VERSION ""

NS_ :

BS_:

BU_: PCU
VAL_TABLE_ a 15 "Fault" 14 "TBD" 13 "TBD" 12 "TBD" 11 "TBD" 10 "TBD" 9 "TBD" 8 "Power Up" 7 "Batt Temp High - Cooling" 6 "Batt Temp Low - Heating" 5 "Charge Complete" 4 "OCV Measure In Prg" 3 "Charging" 2 "Ready To Charge" 1 "Discharge" 0 "Park" ;

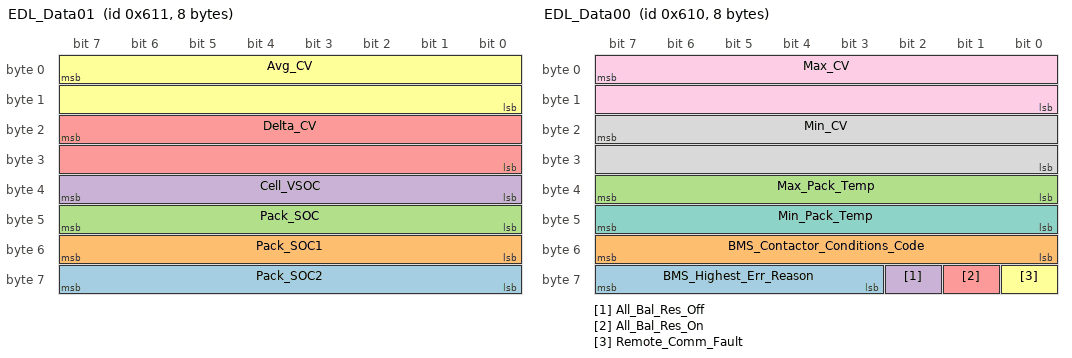
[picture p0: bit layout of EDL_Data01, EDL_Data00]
BO_ 1553 EDL_Data01: 8 Vector__XXX
 SG_ Pack_SOC2 : 63|8@0+ (0.4,0) [0|0] "%" Vector__XXX
 SG_ Pack_SOC1 : 55|8@0+ (0.4,0) [0|0] "%" Vector__XXX
 SG_ Pack_SOC : 47|8@0+ (0.4,0) [0|0] "%" Vector__XXX
 SG_ Cell_VSOC : 39|8@0+ (0.4,0) [0|0] "%" Vector__XXX
 SG_ Delta_CV : 23|16@0+ (0.00244140625,0) [0|0] "Volts" Vector__XXX
 SG_ Avg_CV : 7|16@0+ (0.00244140625,0) [0|0] "Volts" Vector__XXX

BO_ 1827 History_Flt_Msg: 8 Vector__XXX
 SG_ History_Flt_Hi_Cont_Coil_Current : 45|1@0+ (1,0) [0|0] "" Vector__XXX
 SG_ History_Flt_12V_Input_UV_Warning : 44|1@0+ (1,0) [0|0] "" Vector__XXX
 SG_ History_Flt_String_V_Mismatch : 43|1@0+ (1,0) [0|0] "" Vector__XXX
 SG_ History_Flt_Slave_Comm : 42|1@0+ (1,0) [0|0] "" Vector__XXX
 SG_ History_Flt_Hi_DChg_During_Chg : 41|1@0+ (1,0) [0|0] "" Vector__XXX
 SG_ History_Flt_Lo_DChg_During_Chg : 40|1@0+ (1,0) [0|0] "" Vector__XXX
 SG_ History_Flt_12V_Input_Under_Volt : 39|1@0+ (1,0) [0|0] "" Vector__XXX
 SG_ History_Flt_Sec_ContB_Open : 36|1@0+ (1,0) [0|0] "" Vector__XXX
 SG_ History_Flt_Over_Cur_Regulation : 38|1@0+ (1,0) [0|0] "" Vector__XXX
 SG_ History_Flt_No_PCU_Data : 37|1@0+ (1,0) [0|0] "" Vector__XXX
 SG_ History_Flt_Cont2_Stuck_Open : 35|1@0+ (1,0) [0|0] "" Vector__XXX
 SG_ History_Flt_Cont2_Dropout_2nd : 32|1@0+ (1,0) [0|0] "" Vector__XXX
 SG_ History_Flt_Cont2_Dropout_1st : 33|1@0+ (1,0) [0|0] "" Vector__XXX
 SG_ History_Flt_Cont1_Stuck_Open : 34|1@0+ (1,0) [0|0] "" Vector__XXX
 SG_ History_Flt_Under_Volt_B : 26|1@0+ (1,0) [0|0] "" Vector__XXX
 SG_ History_Flt_Under_Volt_A : 27|1@0+ (1,0) [0|0] "" Vector__XXX
 SG_ History_Flt_Under_Temp : 20|1@0+ (1,0) [0|0] "" Vector__XXX
 SG_ History_Flt_SPI : 31|1@0+ (1,0) [0|0] "" Vector__XXX
 SG_ History_Flt_Sec_Stuck_On : 7|1@0+ (1,0) [0|0] "" Vector__XXX
 SG_ History_Flt_Sec_ContA_Open : 10|1@0+ (1,0) [0|0] "" Vector__XXX
 SG_ History_Flt_PChg_Short : 11|1@0+ (1,0) [0|0] "" Vector__XXX
 SG_ History_Flt_PChg_Retry : 14|1@0+ (1,0) [0|0] "" Vector__XXX
 SG_ History_Flt_PChg : 15|1@0+ (1,0) [0|0] "" Vector__XXX
 SG_ History_Flt_Pack_Volt_AD : 1|1@0+ (1,0) [0|0] "" Vector__XXX
 SG_ History_Flt_Over_Volt_B : 28|1@0+ (1,0) [0|0] "" Vector__XXX
 SG_ History_Flt_Over_Volt_A : 29|1@0+ (1,0) [0|0] "" Vector__XXX
 SG_ History_Flt_Over_Temp : 21|1@0+ (1,0) [0|0] "" Vector__XXX
 SG_ History_Flt_Over_Cur : 30|1@0+ (1,0) [0|0] "" Vector__XXX
 SG_ History_Flt_No_Chg_Cur : 18|1@0+ (1,0) [0|0] "" Vector__XXX
 SG_ History_Flt_Int_Iso : 8|1@0+ (1,0) [0|0] "" Vector__XXX
 SG_ History_Flt_Fan_Cur_Lo : 22|1@0+ (1,0) [0|0] "" Vector__XXX
 SG_ History_Flt_Fan_Cur_Hi : 23|1@0+ (1,0) [0|0] "" Vector__XXX
 SG_ History_Flt_Ext_Iso : 9|1@0+ (1,0) [0|0] "" Vector__XXX
 SG_ History_Flt_Cur_B_Lo_AD : 3|1@0+ (1,0) [0|0] "" Vector__XXX
 SG_ History_Flt_Cur_B_Hi_AD : 2|1@0+ (1,0) [0|0] "" Vector__XXX
 SG_ History_Flt_Cur_A_Lo_AD : 5|1@0+ (1,0) [0|0] "" Vector__XXX
 SG_ History_Flt_Cur_A_Hi_AD : 4|1@0+ (1,0) [0|0] "" Vector__XXX
 SG_ History_Flt_Cont1_Dropout_2nd : 12|1@0+ (1,0) [0|0] "" Vector__XXX
 SG_ History_Flt_Cont1_Dropout_1st : 13|1@0+ (1,0) [0|0] "" Vector__XXX
 SG_ History_Flt_Cont2_Stuck_On : 17|1@0+ (1,0) [0|0] "" Vector__XXX
 SG_ History_Flt_Cont2_Retry : 16|1@0+ (1,0) [0|0] "" Vector__XXX
 SG_ History_Flt_Cont1_Stuck_On : 25|1@0+ (1,0) [0|0] "" Vector__XXX
 SG_ History_Flt_Cont1_Retry : 24|1@0+ (1,0) [0|0] "" Vector__XXX
 SG_ History_Flt_Bus_Volt_AD : 0|1@0+ (1,0) [0|0] "" Vector__XXX
 SG_ History_Flt_Bd_Under_Temp : 6|1@0+ (1,0) [0|0] "" Vector__XXX
 SG_ History_Flt_Bd_Over_Temp : 19|1@0+ (1,0) [0|0] "" Vector__XXX

BO_ 1826 Latched_Flt_Msg: 8 Vector__XXX
 SG_ Latched_Flt_Hi_Cont_Coil_Current : 45|1@0+ (1,0) [0|0] "" Vector__XXX
 SG_ Latched_Flt_12V_Input_UV_Warning : 44|1@0+ (1,0) [0|0] "" Vector__XXX
 SG_ Latched_Flt_String_V_Mismatch : 43|1@0+ (1,0) [0|0] "" Vector__XXX
 SG_ Latched_Flt_Slave_Comm : 42|1@0+ (1,0) [0|0] "" Vector__XXX
 SG_ Latched_Flt_Hi_DChg_During_Chg : 41|1@0+ (1,0) [0|0] "" Vector__XXX
 SG_ Latched_Flt_Lo_DChg_During_Chg : 40|1@0+ (1,0) [0|0] "" Vector__XXX
 SG_ Latched_Flt_12V_Input_Under_Volt : 39|1@0+ (1,0) [0|0] "" Vector__XXX
 SG_ Latched_Flt_Sec_ContB_Open : 36|1@0+ (1,0) [0|0] "" Vector__XXX
 SG_ Latched_Flt_Over_Cur_Regulation : 38|1@0+ (1,0) [0|0] "" Vector__XXX
 SG_ Latched_Flt_No_PCU_Data : 37|1@0+ (1,0) [0|0] "" Vector__XXX
 SG_ Latched_Flt_Cont2_Stuck_Open : 35|1@0+ (1,0) [0|0] "" Vector__XXX
 SG_ Latched_Flt_Cont2_Dropout_2nd : 32|1@0+ (1,0) [0|0] "" Vector__XXX
 SG_ Latched_Flt_Cont2_Dropout_1st : 33|1@0+ (1,0) [0|0] "" Vector__XXX
 SG_ Latched_Flt_Cont1_Stuck_Open : 34|1@0+ (1,0) [0|0] "" Vector__XXX
 SG_ Latched_Flt_Under_Volt_B : 26|1@0+ (1,0) [0|0] "" Vector__XXX
 SG_ Latched_Flt_Under_Volt_A : 27|1@0+ (1,0) [0|0] "" Vector__XXX
 SG_ Latched_Flt_Under_Temp : 20|1@0+ (1,0) [0|0] "" Vector__XXX
 SG_ Latched_Flt_SPI : 31|1@0+ (1,0) [0|0] "" Vector__XXX
 SG_ Latched_Flt_Sec_Stuck_On : 7|1@0+ (1,0) [0|0] "" Vector__XXX
 SG_ Latched_Flt_Sec_ContA_Open : 10|1@0+ (1,0) [0|0] "" Vector__XXX
 SG_ Latched_Flt_PChg_Short : 11|1@0+ (1,0) [0|0] "" Vector__XXX
 SG_ Latched_Flt_PChg_Retry : 14|1@0+ (1,0) [0|0] "" Vector__XXX
 SG_ Latched_Flt_PChg : 15|1@0+ (1,0) [0|0] "" Vector__XXX
 SG_ Latched_Flt_Pack_Volt_AD : 1|1@0+ (1,0) [0|0] "" Vector__XXX
 SG_ Latched_Flt_Over_Volt_B : 28|1@0+ (1,0) [0|0] "" Vector__XXX
 SG_ Latched_Flt_Over_Volt_A : 29|1@0+ (1,0) [0|0] "" Vector__XXX
 SG_ Latched_Flt_Over_Temp : 21|1@0+ (1,0) [0|0] "" Vector__XXX
 SG_ Latched_Flt_Over_Cur : 30|1@0+ (1,0) [0|0] "" Vector__XXX
 SG_ Latched_Flt_No_Chg_Cur : 18|1@0+ (1,0) [0|0] "" Vector__XXX
 SG_ Latched_Flt_Int_Iso : 8|1@0+ (1,0) [0|0] "" Vector__XXX
 SG_ Latched_Flt_Fan_Cur_Lo : 22|1@0+ (1,0) [0|0] "" Vector__XXX
 SG_ Latched_Flt_Fan_Cur_Hi : 23|1@0+ (1,0) [0|0] "" Vector__XXX
 SG_ Latched_Flt_Ext_Iso : 9|1@0+ (1,0) [0|0] "" Vector__XXX
 SG_ Latched_Flt_Cur_B_Lo_AD : 3|1@0+ (1,0) [0|0] "" Vector__XXX
 SG_ Latched_Flt_Cur_B_Hi_AD : 2|1@0+ (1,0) [0|0] "" Vector__XXX
 SG_ Latched_Flt_Cur_A_Lo_AD : 5|1@0+ (1,0) [0|0] "" Vector__XXX
 SG_ Latched_Flt_Cur_A_Hi_AD : 4|1@0+ (1,0) [0|0] "" Vector__XXX
 SG_ Latched_Flt_Cont1_Dropout_2nd : 12|1@0+ (1,0) [0|0] "" Vector__XXX
 SG_ Latched_Flt_Cont1_Dropout_1st : 13|1@0+ (1,0) [0|0] "" Vector__XXX
 SG_ Latched_Flt_Cont2_Stuck_On : 17|1@0+ (1,0) [0|0] "" Vector__XXX
 SG_ Latched_Flt_Cont2_Retry : 16|1@0+ (1,0) [0|0] "" Vector__XXX
 SG_ Latched_Flt_Cont1_Stuck_On : 25|1@0+ (1,0) [0|0] "" Vector__XXX
 SG_ Latched_Flt_Cont1_Retry : 24|1@0+ (1,0) [0|0] "" Vector__XXX
 SG_ Latched_Flt_Bus_Volt_AD : 0|1@0+ (1,0) [0|0] "" Vector__XXX
 SG_ Latched_Flt_Bd_Under_Temp : 6|1@0+ (1,0) [0|0] "" Vector__XXX
 SG_ Latched_Flt_Bd_Over_Temp : 19|1@0+ (1,0) [0|0] "" Vector__XXX

BO_ 1825 Active_Flt_Msg: 8 Vector__XXX
 SG_ Active_Flt_Hi_Cont_Coil_Current : 45|1@0+ (1,0) [0|0] "" Vector__XXX
 SG_ Active_Flt_12V_Input_UV_Warning : 44|1@0+ (1,0) [0|0] "" Vector__XXX
 SG_ Active_Flt_String_V_Mismatch : 43|1@0+ (1,0) [0|0] "" Vector__XXX
 SG_ Active_Flt_Slave_Comm : 42|1@0+ (1,0) [0|0] "" Vector__XXX
 SG_ Active_Flt_Hi_DChg_During_Chg : 41|1@0+ (1,0) [0|0] "" Vector__XXX
 SG_ Active_Flt_Lo_DChg_During_Chg : 40|1@0+ (1,0) [0|0] "" Vector__XXX
 SG_ Active_Flt_12V_Input_Under_Volt : 39|1@0+ (1,0) [0|0] "" Vector__XXX
 SG_ Active_Flt_Over_Cur_Regulation : 38|1@0+ (1,0) [0|0] "" Vector__XXX
 SG_ Active_Flt_No_PCU_Data : 37|1@0+ (1,0) [0|0] "" Vector__XXX
 SG_ Active_Flt_Cont2_Stuck_Open : 35|1@0+ (1,0) [0|0] "" Vector__XXX
 SG_ Active_Flt_Cont1_Stuck_Open : 34|1@0+ (1,0) [0|0] "" Vector__XXX
 SG_ Active_Flt_Cont2_Dropout_2nd : 32|1@0+ (1,0) [0|0] "" Vector__XXX
 SG_ Active_Flt_Cont2_Dropout_1st : 33|1@0+ (1,0) [0|0] "" Vector__XXX
 SG_ Active_Flt_Sec_ContB_Open : 36|1@0+ (1,0) [0|0] "" Vector__XXX
 SG_ Active_Flt_Under_Volt_B : 26|1@0+ (1,0) [0|0] "" Vector__XXX
 SG_ Active_Flt_Under_Volt_A : 27|1@0+ (1,0) [0|0] "" Vector__XXX
 SG_ Active_Flt_Under_Temp : 20|1@0+ (1,0) [0|0] "" Vector__XXX
 SG_ Active_Flt_SPI : 31|1@0+ (1,0) [0|0] "" Vector__XXX
 SG_ Active_Flt_Sec_Stuck_On : 7|1@0+ (1,0) [0|0] "" Vector__XXX
 SG_ Active_Flt_Sec_ContA_Open : 10|1@0+ (1,0) [0|0] "" Vector__XXX
 SG_ Active_Flt_PChg_Short : 11|1@0+ (1,0) [0|0] "" Vector__XXX
 SG_ Active_Flt_PChg_Retry : 14|1@0+ (1,0) [0|0] "" Vector__XXX
 SG_ Active_Flt_PChg : 15|1@0+ (1,0) [0|0] "" Vector__XXX
 SG_ Active_Flt_Pack_Volt_AD : 1|1@0+ (1,0) [0|0] "" Vector__XXX
 SG_ Active_Flt_Over_Volt_B : 28|1@0+ (1,0) [0|0] "" Vector__XXX
 SG_ Active_Flt_Over_Volt_A : 29|1@0+ (1,0) [0|0] "" Vector__XXX
 SG_ Active_Flt_Over_Temp : 21|1@0+ (1,0) [0|0] "" Vector__XXX
 SG_ Active_Flt_Over_Cur : 30|1@0+ (1,0) [0|0] "" Vector__XXX
 SG_ Active_Flt_No_Chg_Cur : 18|1@0+ (1,0) [0|0] "" Vector__XXX
 SG_ Active_Flt_Int_Iso : 8|1@0+ (1,0) [0|0] "" Vector__XXX
 SG_ Active_Flt_Fan_Cur_Lo : 22|1@0+ (1,0) [0|0] "" Vector__XXX
 SG_ Active_Flt_Fan_Cur_Hi : 23|1@0+ (1,0) [0|0] "" Vector__XXX
 SG_ Active_Flt_Ext_Iso : 9|1@0+ (1,0) [0|0] "" Vector__XXX
 SG_ Active_Flt_Cur_B_Lo_AD : 3|1@0+ (1,0) [0|0] "" Vector__XXX
 SG_ Active_Flt_Cur_B_Hi_AD : 2|1@0+ (1,0) [0|0] "" Vector__XXX
 SG_ Active_Flt_Cur_A_Lo_AD : 5|1@0+ (1,0) [0|0] "" Vector__XXX
 SG_ Active_Flt_Cur_A_Hi_AD : 4|1@0+ (1,0) [0|0] "" Vector__XXX
 SG_ Active_Flt_Cont1_Dropout_2nd : 12|1@0+ (1,0) [0|0] "" Vector__XXX
 SG_ Active_Flt_Cont1_Dropout_1st : 13|1@0+ (1,0) [0|0] "" Vector__XXX
 SG_ Active_Flt_Cont2_Stuck_On : 17|1@0+ (1,0) [0|0] "" Vector__XXX
 SG_ Active_Flt_Cont2_Retry : 16|1@0+ (1,0) [0|0] "" Vector__XXX
 SG_ Active_Flt_Cont1_Stuck_On : 25|1@0+ (1,0) [0|0] "" Vector__XXX
 SG_ Active_Flt_Cont1_Retry : 24|1@0+ (1,0) [0|0] "" Vector__XXX
 SG_ Active_Flt_Bus_Volt_AD : 0|1@0+ (1,0) [0|0] "" Vector__XXX
 SG_ Active_Flt_Bd_Under_Temp : 6|1@0+ (1,0) [0|0] "" Vector__XXX
 SG_ Active_Flt_Bd_Over_Temp : 19|1@0+ (1,0) [0|0] "" Vector__XXX

BO_ 783 Msg_30F: 8 Vector__XXX
 SG_ BMS_Serial_Number_Bytes_9_16 : 7|64@0+ (1,0) [0|1.84467E+019] "" Vector__XXX

BO_ 782 Msg_30E: 8 Vector__XXX
 SG_ BMS_Serial_Number_Bytes_1_8 : 7|64@0+ (1,0) [0|1.84467E+019] "" Vector__XXX

BO_ 1552 EDL_Data00: 8 Vector__XXX
 SG_ BMS_Highest_Err_Reason : 63|5@0+ (1,0) [0|0] "" Vector__XXX
 SG_ BMS_Contactor_Conditions_Code : 55|8@0+ (1,0) [0|0] "" Vector__XXX
 SG_ Max_Pack_Temp : 39|8@0- (1,0) [0|0] "" Vector__XXX
 SG_ All_Bal_Res_Off : 58|1@0+ (1,0) [0|0] "" Vector__XXX
 SG_ All_Bal_Res_On : 57|1@0+ (1,0) [0|0] "" Vector__XXX
 SG_ Remote_Comm_Fault : 56|1@0+ (1,0) [0|0] "" Vector__XXX
 SG_ Min_Pack_Temp : 47|8@0- (1,0) [0|0] "" Vector__XXX
 SG_ Min_CV : 23|16@0+ (0.00244140625,0) [0|0] "Volts" Vector__XXX
 SG_ Max_CV : 7|16@0+ (0.00244140625,0) [0|0] "Volts" Vector__XXX

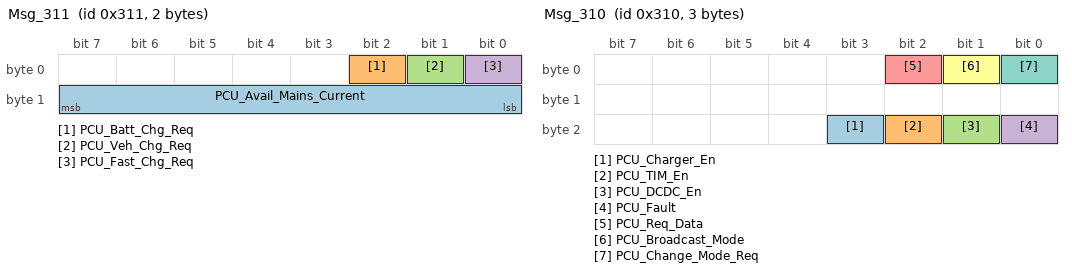
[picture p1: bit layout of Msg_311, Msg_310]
BO_ 785 Msg_311: 2 Vector__XXX
 SG_ PCU_Avail_Mains_Current : 15|8@0+ (0.2,0) [0|0] "Amps" Vector__XXX
 SG_ PCU_Batt_Chg_Req : 2|1@0+ (1,0) [0|0] "T/F" Vector__XXX
 SG_ PCU_Veh_Chg_Req : 1|1@0+ (1,0) [0|0] "T/F" Vector__XXX
 SG_ PCU_Fast_Chg_Req : 0|1@0+ (1,0) [0|0] "T/F" Vector__XXX

BO_ 784 Msg_310: 3 Vector__XXX
 SG_ PCU_Charger_En : 19|1@0+ (1,0) [0|0] "T/F" Vector__XXX
 SG_ PCU_TIM_En : 18|1@0+ (1,0) [0|0] "T/F" Vector__XXX
 SG_ PCU_DCDC_En : 17|1@0+ (1,0) [0|0] "T/F" Vector__XXX
 SG_ PCU_Fault : 16|1@0+ (1,0) [0|0] "T/F" Vector__XXX
 SG_ PCU_Req_Data : 2|1@0+ (1,0) [0|0] "T/F" Vector__XXX
 SG_ PCU_Broadcast_Mode : 1|1@0+ (1,0) [0|0] "T/F" Vector__XXX
 SG_ PCU_Change_Mode_Req : 0|1@0+ (1,0) [0|0] "T/F" Vector__XXX

BO_ 35 Msg_023: 1 Vector__XXX
 SG_ RCM_Fuel_Cutoff : 6|2@0+ (1,0) [0|0] "" Vector__XXX
 SG_ RCM_Airbag_Deployed : 7|1@0+ (1,0) [0|0] "T/F" Vector__XXX

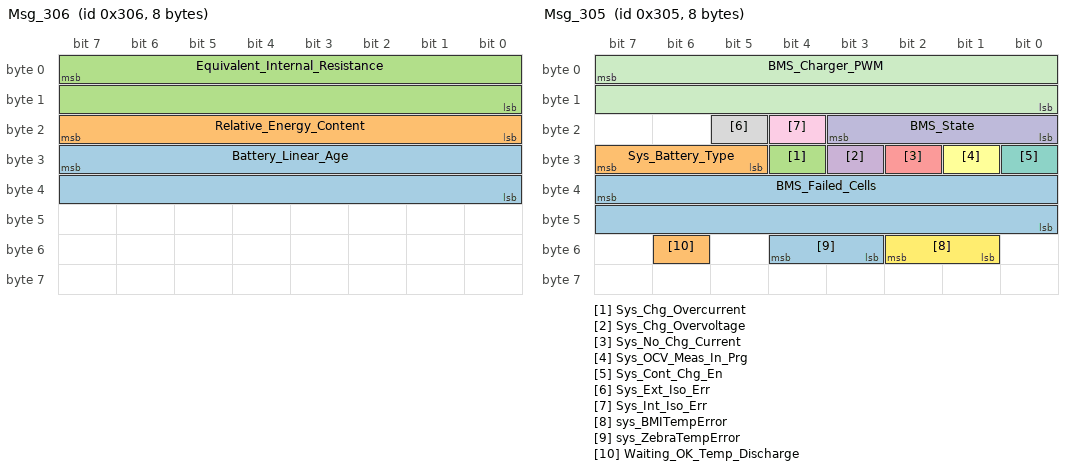
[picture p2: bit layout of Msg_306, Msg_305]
BO_ 774 Msg_306: 8 Vector__XXX
 SG_ Battery_Linear_Age : 31|16@0+ (1,0) [0|65535] "" Vector__XXX
 SG_ Relative_Energy_Content : 23|8@0+ (0.5,0) [0|100] "%" Vector__XXX
 SG_ Equivalent_Internal_Resistance : 7|16@0+ (0.001,0) [0|65.535] "Ohms" Vector__XXX

BO_ 773 Msg_305: 8 Vector__XXX
 SG_ BMS_Failed_Cells : 39|16@0+ (1,0) [0|0] "" Vector__XXX
 SG_ Sys_Battery_Type : 31|3@0+ (1,0) [0|0] "" Vector__XXX
 SG_ Sys_Chg_Overcurrent : 28|1@0+ (1,0) [0|0] "T/F" Vector__XXX
 SG_ Sys_Chg_Overvoltage : 27|1@0+ (1,0) [0|0] "T/F" Vector__XXX
 SG_ Sys_No_Chg_Current : 26|1@0+ (1,0) [0|0] "T/F" Vector__XXX
 SG_ Sys_OCV_Meas_In_Prg : 25|1@0+ (1,0) [0|0] "T/F" Vector__XXX
 SG_ Sys_Cont_Chg_En : 24|1@0+ (1,0) [0|0] "T/F" Vector__XXX
 SG_ Sys_Ext_Iso_Err : 21|1@0+ (1,0) [0|0] "T/F" Vector__XXX
 SG_ Sys_Int_Iso_Err : 20|1@0+ (1,0) [0|0] "T/F" Vector__XXX
 SG_ BMS_State : 19|4@0+ (1,0) [0|0] "" Vector__XXX
 SG_ BMS_Charger_PWM : 7|16@0+ (0.1,0) [0|0] "%" Vector__XXX
 SG_ sys_BMITempError : 50|2@0+ (1,0) [0|3] ""  PCU
 SG_ sys_ZebraTempError : 52|2@0+ (1,0) [0|3] ""  PCU
 SG_ Waiting_OK_Temp_Discharge : 54|1@0+ (1,0) [0|1] ""  PCU

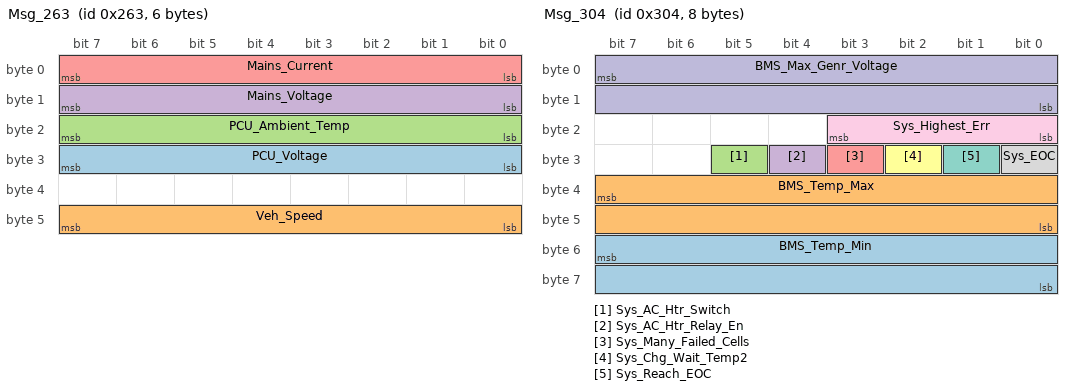
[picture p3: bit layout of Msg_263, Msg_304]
BO_ 611 Msg_263: 6 Vector__XXX
 SG_ PCU_Voltage : 31|8@0+ (0.1,0) [0|0] "Volts" Vector__XXX
 SG_ Veh_Speed : 47|8@0+ (0.5,0) [0|0] "kmh" Vector__XXX
 SG_ PCU_Ambient_Temp : 23|8@0- (0.5,0) [0|0] "DegC" Vector__XXX
 SG_ Mains_Voltage : 15|8@0+ (1,0) [0|0] "Volts" Vector__XXX
 SG_ Mains_Current : 7|8@0- (0.2,0) [0|0] "Amps" Vector__XXX

BO_ 772 Msg_304: 8 Vector__XXX
 SG_ BMS_Temp_Min : 55|16@0- (0.1,0) [0|0] "DegC" Vector__XXX
 SG_ BMS_Temp_Max : 39|16@0- (0.1,0) [0|0] "DegC" Vector__XXX
 SG_ Sys_AC_Htr_Switch : 29|1@0+ (1,0) [0|0] "T/F" Vector__XXX
 SG_ Sys_AC_Htr_Relay_En : 28|1@0+ (1,0) [0|0] "T/F" Vector__XXX
 SG_ Sys_Many_Failed_Cells : 27|1@0+ (1,0) [0|0] "T/F" Vector__XXX
 SG_ Sys_Chg_Wait_Temp2 : 26|1@0+ (1,0) [0|0] "T/F" Vector__XXX
 SG_ Sys_Reach_EOC : 25|1@0+ (1,0) [0|0] "T/F" Vector__XXX
 SG_ Sys_EOC : 24|1@0+ (1,0) [0|0] "T/F" Vector__XXX
 SG_ Sys_Highest_Err : 19|4@0+ (1,0) [0|0] "" Vector__XXX
 SG_ BMS_Max_Genr_Voltage : 7|16@0+ (0.1,0) [0|0] "Volts" Vector__XXX

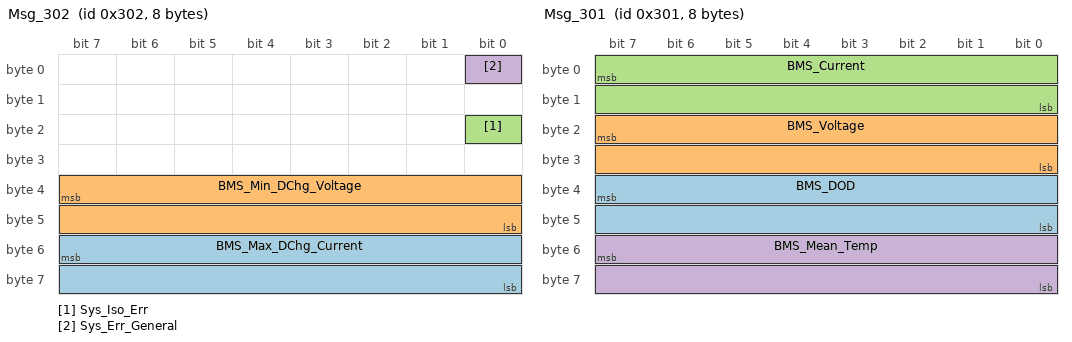
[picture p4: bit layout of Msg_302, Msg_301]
BO_ 770 Msg_302: 8 Vector__XXX
 SG_ BMS_Max_DChg_Current : 55|16@0+ (0.1,0) [0|0] "Amps" Vector__XXX
 SG_ BMS_Min_DChg_Voltage : 39|16@0+ (0.1,0) [0|0] "Volts" Vector__XXX
 SG_ Sys_Iso_Err : 16|1@0+ (1,0) [0|0] "T/F" Vector__XXX
 SG_ Sys_Err_General : 0|1@0+ (1,0) [0|0] "T/F" Vector__XXX

BO_ 769 Msg_301: 8 Vector__XXX
 SG_ BMS_DOD : 39|16@0+ (0.1,0) [0|0] "%" Vector__XXX
 SG_ BMS_Voltage : 23|16@0+ (0.1,0) [0|0] "Volts" Vector__XXX
 SG_ BMS_Current : 7|16@0- (0.1,0) [0|0] "Amps" Vector__XXX
 SG_ BMS_Mean_Temp : 55|16@0- (0.1,0) [0|0] "DegC" Vector__XXX

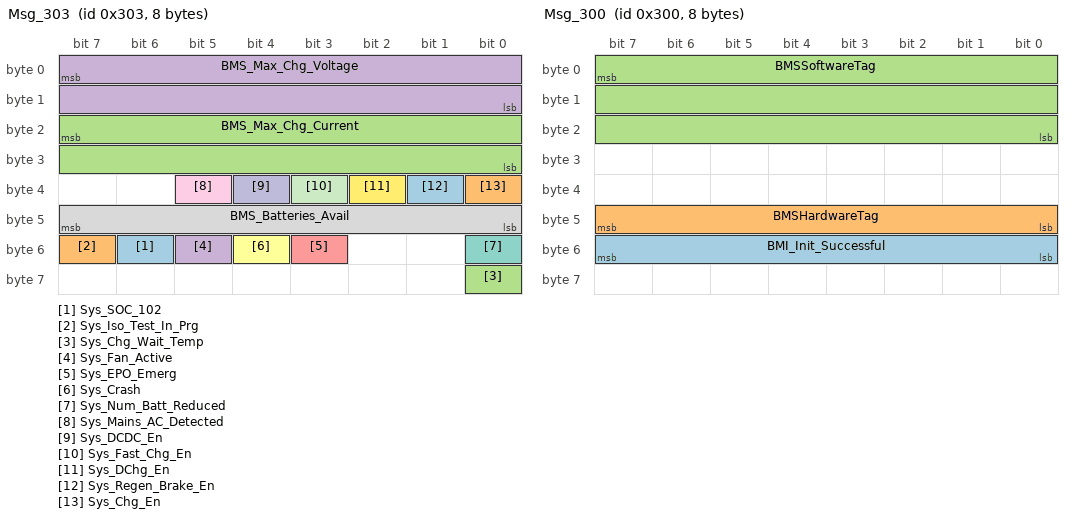
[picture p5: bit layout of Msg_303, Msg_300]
BO_ 771 Msg_303: 8 Vector__XXX
 SG_ Sys_SOC_102 : 54|1@0+ (1,0) [0|0] "T/F" Vector__XXX
 SG_ Sys_Iso_Test_In_Prg : 55|1@0+ (1,0) [0|0] "T/F" Vector__XXX
 SG_ Sys_Chg_Wait_Temp : 56|1@0+ (1,0) [0|0] "T/F" Vector__XXX
 SG_ Sys_Fan_Active : 53|1@0+ (1,0) [0|0] "T/F" Vector__XXX
 SG_ Sys_EPO_Emerg : 51|1@0+ (1,0) [0|0] "T/F" Vector__XXX
 SG_ Sys_Crash : 52|1@0+ (1,0) [0|0] "T/F" Vector__XXX
 SG_ Sys_Num_Batt_Reduced : 48|1@0+ (1,0) [0|0] "T/F" Vector__XXX
 SG_ BMS_Batteries_Avail : 47|8@0+ (1,0) [0|0] "" Vector__XXX
 SG_ Sys_Mains_AC_Detected : 37|1@0+ (1,0) [0|0] "T/F" Vector__XXX
 SG_ Sys_DCDC_En : 36|1@0+ (1,0) [0|0] "T/F" Vector__XXX
 SG_ Sys_Fast_Chg_En : 35|1@0+ (1,0) [0|0] "T/F" Vector__XXX
 SG_ Sys_DChg_En : 34|1@0+ (1,0) [0|0] "T/F" Vector__XXX
 SG_ Sys_Regen_Brake_En : 33|1@0+ (1,0) [0|0] "T/F" Vector__XXX
 SG_ Sys_Chg_En : 32|1@0+ (1,0) [0|0] "T/F" Vector__XXX
 SG_ BMS_Max_Chg_Current : 23|16@0+ (0.1,0) [0|0] "Amps" Vector__XXX
 SG_ BMS_Max_Chg_Voltage : 7|16@0+ (0.1,0) [0|0] "Volts" Vector__XXX

BO_ 768 Msg_300: 8 Vector__XXX
 SG_ BMI_Init_Successful : 55|8@0+ (1,0) [0|255] ""  PCU
 SG_ BMSHardwareTag : 47|8@0+ (1,0) [0|1] ""  PCU
 SG_ BMSSoftwareTag : 7|24@0+ (1,0) [0|16777215] ""  PCU

CM_ "<<BITRODE
BAUDRATE=500000
>>";
BA_DEF_  "BusType" STRING ;
BA_DEF_DEF_  "BusType" "CAN";
